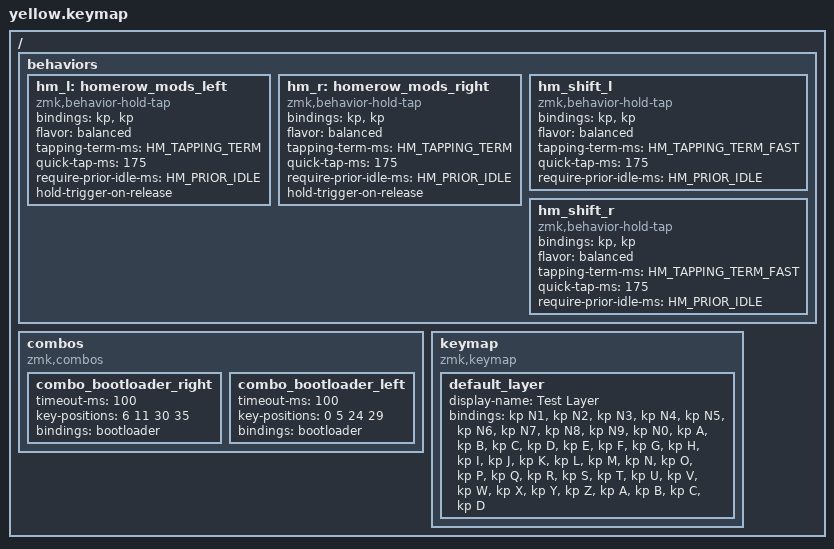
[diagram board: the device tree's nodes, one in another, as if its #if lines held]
/*
 * Copyright (c) 2020 The ZMK Contributors
 *
 * SPDX-License-Identifier: MIT
 */

#include <behaviors.dtsi>
#include <dt-bindings/zmk/keys.h>
#include <locale/keys_de.h>
#include <dt-bindings/zmk/bt.h>
#include <dt-bindings/zmk/ext_power.h>
#include <dt-bindings/zmk/outputs.h>

#define TEST_LAYER
#undef TEST_LAYER

#define HM_TAPPING_TERM 300
#define HM_TAPPING_TERM_FAST 200
#define HM_PRIOR_IDLE 150

#define DEFAULT   0
#define LOWER     1
#define RAISE     2
#define ADJUST    3
#define F_KEYS    4
#define SYMBOLS_L 5
#define SYMBOLS_R 6
#define NAVNUM    7

#define DE_AE (DE_A_UMLAUT)
#define DE_OE (DE_O_UMLAUT)
#define DE_UE (DE_U_UMLAUT)

#define _LOW_RET &lt LOWER RET
#define _RAI_RET &lt RAISE RET
#define _NAV_SPC &lt NAVNUM SPACE
#define PO_OFF &ext_power EP_OFF
#define SO_OFF &soft_off
#define RESET &sys_reset

// home row mods with timeless behaviour
#define HMRLU &hm_l LGUI U
#define HMRLI &hm_l LALT I
#define HMRLA &hm_l LCTRL A
#define HMRLE &hm_shift_l LSHFT E

#define HMRRN &hm_shift_r RSHFT N 
#define HMRRR &hm_l LCTRL R
#define HMRRT &hm_l LALT T
#define HMRRD &hm_l LGUI D


/ {

    behaviors {

        // Positional Homerow mods
        // Homerow mods that prevent accidental activations when rolling keys,
        // such as when typing `st` or `ne` on colemak-dh layouts or `as` on
        // qwerty.
        //
        // Works by only allowing a mod to activate within tapping-term if
        // it's on the opposite side of the keyboard or on the same side thumb
        // keys.

        // Further optimization using urob's timerless homerow mods method:
        // https://github.com/urob/zmk-config#timeless-homerow-mods
        hm_l: homerow_mods_left {
            compatible = "zmk,behavior-hold-tap";
            #binding-cells = <2>;
            bindings = <&kp>,  <&kp>;

            flavor = "balanced";
            tapping-term-ms = <HM_TAPPING_TERM>;
            quick-tap-ms = <175>;                // repeat on tap-into-hold
            require-prior-idle-ms = <HM_PRIOR_IDLE>;

            /* hold-trigger-key-positions = <KEYS_R KEYS_T>; */
            hold-trigger-on-release;
        };

        hm_r: homerow_mods_right {
            compatible = "zmk,behavior-hold-tap";
            #binding-cells = <2>;
            bindings = <&kp>, <&kp>;

            flavor = "balanced";
            tapping-term-ms = <HM_TAPPING_TERM>;
            quick-tap-ms = <175>;
            require-prior-idle-ms = <HM_PRIOR_IDLE>;

            /* hold-trigger-key-positions = <KEYS_L KEYS_T>; */
            hold-trigger-on-release;
        };


        // Positional Homerow mods for shift
        // Use faster tapping term and disable some features that may
        // cause false negatives.
        hm_shift_l: hm_shift_l {
            compatible = "zmk,behavior-hold-tap";
            #binding-cells = <2>;
            bindings = <&kp>, <&kp>;

            flavor = "balanced";
            tapping-term-ms = <HM_TAPPING_TERM_FAST>;
            quick-tap-ms = <175>;
            require-prior-idle-ms = <HM_PRIOR_IDLE>;

            /* hold-trigger-key-positions = <KEYS_R KEYS_T>; */
            // hold-trigger-on-release;
        };

        hm_shift_r: hm_shift_r {
            compatible = "zmk,behavior-hold-tap";
            #binding-cells = <2>;
            bindings = <&kp>, <&kp>;

            flavor = "balanced";
            tapping-term-ms = <HM_TAPPING_TERM_FAST>;
            quick-tap-ms = <175>;
            require-prior-idle-ms = <HM_PRIOR_IDLE>;

            /* hold-trigger-key-positions = <KEYS_L KEYS_T>; */
            // hold-trigger-on-release;
        };
    }; // behaviors

    combos {
      compatible = "zmk,combos";
      combo_bootloader_right {
        timeout-ms = <100>;
        key-positions = <6 11 30 35>;  /* all 4 corners of left half */
        bindings = <&bootloader>;
      };
      combo_bootloader_left {
        timeout-ms = <100>;
        key-positions = <0 5 24 29>;  /* all 4 corners of left half */
        bindings = <&bootloader>;
      };
    };  // combos

    keymap {
      compatible = "zmk,keymap";
#ifdef TEST_LAYER
      default_layer {
        display-name = "Test Layer";
        bindings = <
      /*┌────────┬────────┬────────┬────────┬────────┬───────────┐ ┌────────┬────────┬────────┬────────┬───────┬───────┐ */
          &kp N1   &kp N2   &kp N3   &kp N4   &kp N5    &kp N6       &kp N7   &kp N8   &kp N9   &kp N0   &kp A   &kp B
      /*├────────┼────────┼────────┼────────┼────────┼───────────┤ ├────────┼────────┼────────┼────────┼───────┼───────┤ */
          &kp C    &kp D    &kp E    &kp F    &kp G     &kp H        &kp I    &kp J    &kp K    &kp L    &kp M   &kp N
      /*├────────┼────────┼────────┼────────┼────────┼───────────┤ ├────────┼────────┼────────┼────────┼───────┼───────┤ */
          &kp O    &kp P    &kp Q    &kp R    &kp S     &kp T        &kp U    &kp V    &kp W    &kp X    &kp Y   &kp Z
      /*└────────┴────────┴────────┴────────┼────────┼───────────┤ ├────────┼────────┼────────┴────────┴───────┴───────┘ */
                                              &kp A     &kp B        &kp C    &kp D
      /*                                    └────────┴───────────┘ └────────┴────────┘                                   */
        >;
      };
#else
      neo_layer {
        display-name = "NEO2";
        bindings = <
      /*┌──────────────────┬───────────┬───────────┬───────────┬───────────┬───────────┐ ┌───────────┬───────────┬───────────┬───────────┬───────────┬──────────────────┐ */
          &lt F_KEYS TAB    &kp X       &kp V       &kp L       &kp C       &kp W         &kp K       &kp H       &kp G       &kp F       &kp Q       &kp BSPC
      /*├──────────────────┼───────────┼───────────┼───────────┼───────────┼───────────┤ ├───────────┼───────────┼───────────┼───────────┼───────────┼──────────────────┤ */
          &lt SYMBOLS_L ESC HMRLU       HMRLI       HMRLA       HMRLE       &kp O         &kp S       HMRRN        HMRRR        HMRRT        HMRRD        &lt SYMBOLS_R DE_Y
      /*├──────────────────┼───────────┼───────────┼───────────┼───────────┼───────────┤ ├───────────┼───────────┼───────────┼───────────┼───────────┼──────────────────┤ */
          &kp LSHFT         &kp DE_UE   &kp DE_OE   &kp DE_AE   &kp P       &kp DE_Z      &kp B       &kp M       &kp COMMA   &kp DOT     &kp J       &kp DE_SZ
      /*└──────────────────┴───────────┴───────────┴───────────┼───────────┼───────────┤ ├───────────┼───────────┼───────────┴───────────┴───────────┴──────────────────┘ */
                                                                _LOW_RET    _NAV_SPC      _RAI_RET    _NAV_SPC
      /*                                                       └───────────┴───────────┘ └───────────┴───────────┘                                                     */
        >;
      };

      neo_lower {
        display-name = "NEO2-Lower";
        bindings = <
          &trans &trans &trans &trans &trans RESET        /* */   &trans &trans &trans &trans &trans &kp C_PLAY_PAUSE
          &trans &trans &trans &trans &trans PO_OFF       /* */   &trans &trans &trans &trans &trans &kp C_STOP
          &trans &trans &trans RESET  PO_OFF &bootloader  /* */   &trans &trans &trans &trans &trans &kp C_NEXT
                                      &trans &trans       /* */   &trans &trans
        >;
      };

      neo_raise {
        display-name = "NEO2-Raise";
        bindings = <
          &trans &trans &trans &trans &trans &trans  /* */   &kp HOME    &kp PG_DN &kp PG_UP &kp END   &trans &kp C_VOL_UP
          &trans &trans &trans &trans &trans &trans  /* */   &kp LEFT    &kp DOWN  &kp UP    &kp RIGHT &trans &kp C_VOL_DN
          &trans &trans &trans &trans &trans &trans  /* */   &bootloader PO_OFF    RESET     &trans    &trans &kp C_MUTE
                                      &trans &trans  /* */   &trans      &trans
        >;
      };

      neo_adjust {
        display-name = "NEO2-Adjust";
        bindings = <
          &trans &trans &trans &trans &trans &trans  /* */   &trans &trans &trans &trans &trans &trans
          &trans &trans &trans &trans &trans &trans  /* */   &trans &trans &trans &trans &trans &trans
          &trans &trans &trans &trans &trans &trans  /* */   &trans &trans &trans &trans &trans &trans
                                      &trans &trans  /* */   &trans &trans
        >;
      };

      neo_f_keys {
        display-name = "NEO2-F Keys";
        bindings = <
          &trans       &trans       &trans     &trans &trans &trans  /* */   &trans &kp F7 &kp F8 &kp F9 &kp F10 &kp F11
          &bt BT_SEL 0 &bt BT_SEL 1 &trans     &trans &trans &trans  /* */   &trans &kp F4 &kp F5 &kp F6 &kp F12 &kp F13
          &bt BT_PRV   &bt BT_NXT   &bt BT_CLR &trans &trans &trans  /* */   &trans &kp F1 &kp F2 &kp F3 &trans  &trans
                                               &trans &trans  /* */   &trans &trans
        >;
      };

      neo_symbols_l {
        display-name = "NEO2-Symbols L";
        bindings = <
      /*┌───────────┬────────────┬────────────┬────────────┬────────────┬────────────┐ ┌────────────┬────────────┬────────────┬────────────┬────────────┬────────────┐ */
          &trans     &kp DE_EURO  &kp DE_UNDER &kp DE_LBKT  &kp DE_RBKT  &kp DE_CARET   &kp DE_EXCL  &kp DE_LT    &kp DE_GT    &kp DE_EQUAL &kp DE_AMPS  &trans
      /*├───────────┼────────────┼────────────┼────────────┼────────────┼────────────┤ ├────────────┼────────────┼────────────┼────────────┼────────────┼────────────┤ */
          &trans     &kp DE_BSLH  &kp DE_SLASH &kp DE_LBRC  &kp DE_RBRC  &kp DE_STAR    &kp DE_QMARK &kp DE_LPAR  &kp DE_RPAR  &kp DE_MINUS &kp DE_COLON &kp DE_AT
      /*├───────────┼────────────┼────────────┼────────────┼────────────┼────────────┤ ├────────────┼────────────┼────────────┼────────────┼────────────┼────────────┤ */
          &trans     &kp DE_HASH  &kp DE_DLLR  &kp DE_PIPE  &kp DE_TILDE &kp DE_GRAVE   &kp DE_PLUS  &kp DE_PRCNT &kp DE_DQT   &kp DE_SQT   &kp DE_SEMI  &trans
      /*└───────────┴────────────┴────────────┴────────────┼────────────┼────────────┤ ├────────────┼────────────┼────────────┴────────────┴────────────┴────────────┘ */
                                                            &trans       &trans         &trans       &trans
      /*                                                   └────────────┴────────────┘ └────────────┴────────────┘                                                     */
        >;
      };

      neo_symbols_r {
        display-name = "NEO2-Symbols R";
        bindings = <
      /*┌───────────┬────────────┬────────────┬────────────┬────────────┬────────────┐ ┌────────────┬────────────┬────────────┬────────────┬────────────┬────────────┐ */
         &trans      &kp DE_EURO  &kp DE_UNDER &kp DE_LBKT  &kp DE_RBKT  &kp DE_CARET   &kp DE_EXCL  &kp DE_LT    &kp DE_GT    &kp DE_EQUAL &kp DE_AMPS  &trans
      /*├───────────┼────────────┼────────────┼────────────┼────────────┼────────────┤ ├────────────┼────────────┼────────────┼────────────┼────────────┼────────────┤ */
         &kp DE_AT   &kp DE_BSLH  &kp DE_FSLH  &kp DE_LBRC  &kp DE_RBRC  &kp DE_STAR    &kp DE_QMARK &kp DE_LPAR  &kp DE_RPAR  &kp DE_MINUS &kp DE_COLON &trans
      /*├───────────┼────────────┼────────────┼────────────┼────────────┼────────────┤ ├────────────┼────────────┼────────────┼────────────┼────────────┼────────────┤ */
         &trans      &kp DE_HASH  &kp DE_DLLR  &kp DE_PIPE  &kp DE_TILDE &kp DE_GRAVE   &kp DE_PLUS  &kp DE_PRCNT &kp DE_DQT   &kp DE_SQT   &kp DE_SEMI  &trans
      /*└───────────┴────────────┴────────────┴────────────┼────────────┼────────────┤ ├────────────┼────────────┼────────────┴────────────┴────────────┴────────────┘ */
                                                            &trans       &trans         &trans       &trans
      /*                                                   └────────────┴────────────┘ └────────────┴────────────┘                                                     */
        >;
      };

      neo_navnum {
        display-name = "NEO2-NavNum";
        bindings = <
       /*┌─────────┬─────────┬─────────┬─────────┬─────────┬─────────┐ ┌───────────┬─────────┬─────────┬─────────┬────────────┬─────────┐*/
           &trans    &trans    &trans    &trans    &trans    &trans     &kp DE_FSLH &kp N7    &kp N8    &kp N9    &kp DE_MINUS &trans
       /*├─────────┼─────────┼─────────┼─────────┼─────────┼─────────┤ ├───────────┼─────────┼─────────┼─────────┼────────────┼─────────┤*/
           &trans    &trans    &trans    &trans    &trans    &trans     &kp DE_STAR &kp N4    &kp N5    &kp N6    &kp DE_PLUS  &trans
       /*├─────────┼─────────┼─────────┼─────────┼─────────┼─────────┤ ├───────────┼─────────┼─────────┼─────────┼────────────┼─────────┤*/
           &trans    &trans    &trans    &trans    &trans    &trans     &trans      &kp N1    &kp N2    &kp N3    &kp COMMA    &kp DOT
       /*└─────────┴─────────┴─────────┴─────────┼─────────┼─────────┤ ├───────────┼─────────┼─────────┴─────────┴────────────┴─────────┘*/
                                                   &trans    &trans     &trans      &trans
       /*                                        └─────────┴─────────┘ └───────────┴─────────┘*/
        >;
      };
#endif // TEST_LAYER

    };
};
